# RP2040 register map
Vendor: Raspberry Pi; File version: 2025.06.15
CPU: CM0PLUS r0p1, little endian, 2 interrupt priority bits
Registers are 32-bit, read-write, no defined reset value unless marked. A register's access mark holds for its fields unless they carry their own. Offsets are from the block's base; [hi:lo] are bit positions; {n}, {i} and the like mark numbered series; 'fields as' and 'values as' point back to an identical list.

## USBCTRL_DPRAM — DPRAM layout for USB device.
Base 0x50100000
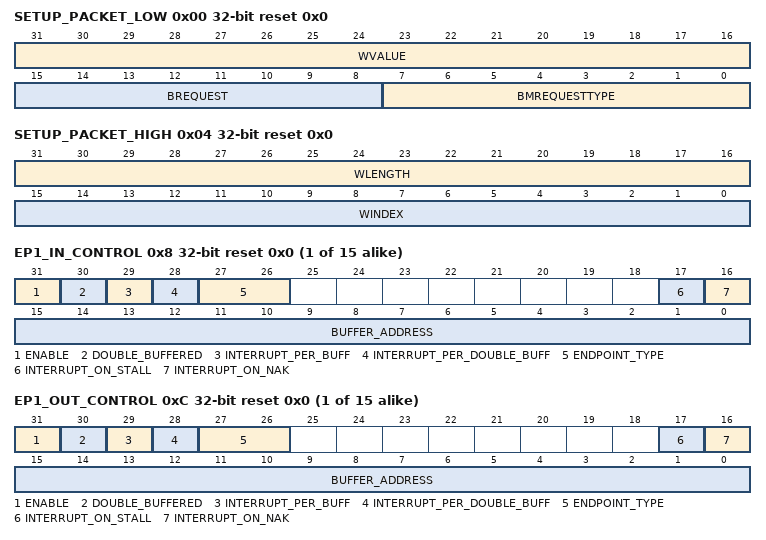
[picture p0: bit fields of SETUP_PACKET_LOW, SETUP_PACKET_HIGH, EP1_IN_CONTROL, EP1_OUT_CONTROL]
0x00 SETUP_PACKET_LOW reset 0x0 — Bytes 0-3 of the SETUP packet from the host.
  [31:16] WVALUE, [15:8] BREQUEST, [7:0] BMREQUESTTYPE
0x04 SETUP_PACKET_HIGH reset 0x0 — Bytes 4-7 of the setup packet from the host.
  [31:16] WLENGTH, [15:0] WINDEX
{0x0+8i} EP{i}_IN_CONTROL reset 0x0 (i=1..15)
  [31] ENABLE — Enable this endpoint. The device will not reply to any packets for this endpoint if this bit is not set.
  [30] DOUBLE_BUFFERED — This endpoint is double buffered.
  [29] INTERRUPT_PER_BUFF — Trigger an interrupt each time a buffer is done.
  [28] INTERRUPT_PER_DOUBLE_BUFF — Trigger an interrupt each time both buffers are done. Only valid in double buffered mode.
  [27:26] ENDPOINT_TYPE
    0=Control; 1=Isochronous; 2=Bulk; 3=Interrupt
  [17] INTERRUPT_ON_STALL — Trigger an interrupt if a STALL is sent. Intended for debug only.
  [16] INTERRUPT_ON_NAK — Trigger an interrupt if a NAK is sent. Intended for debug only.
  [15:0] BUFFER_ADDRESS — 64 byte aligned buffer address for this EP (bits 0-5 are ignored). Relative to the start of the DPRAM.
{0x4+8i} EP{i}_OUT_CONTROL reset 0x0 (i=1..15)
  fields as EP1_IN_CONTROL
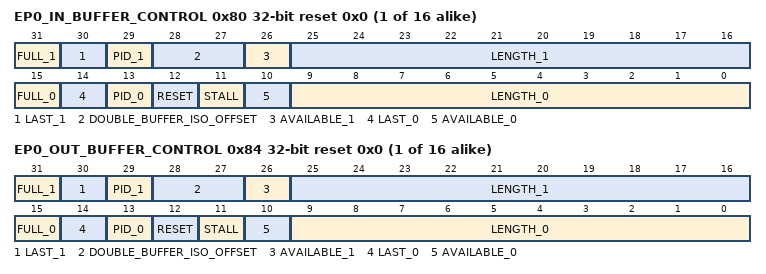
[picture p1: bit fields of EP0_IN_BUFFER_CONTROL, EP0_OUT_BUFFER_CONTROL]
{0x80+8i} EP{i}_IN_BUFFER_CONTROL reset 0x0 (i=0..15) — Buffer control for both buffers of an endpoint. Fields ending in a _1 are for buffer 1. Fields ending in a _0 are for buffer 0. Buffer 1 controls are only valid if the endpoint is in double buffered mode.
  [31] FULL_1 — Buffer 1 is full. For an IN transfer (TX to the host) the bit is set to indicate the data is valid. For an OUT transfer (RX from the host) this bit should be left as a 0. The host will set it when it has filled the buffer with data.
  [30] LAST_1 — Buffer 1 is the last buffer of the transfer.
  [29] PID_1 — The data pid of buffer 1.
  [28:27] DOUBLE_BUFFER_ISO_OFFSET — The number of bytes buffer 1 is offset from buffer 0 in Isochronous mode. Only valid in double buffered mode for an Isochronous endpoint. For a non Isochronous endpoint the offset is always 64 bytes.
    0=128; 1=256; 2=512; 3=1024
  [26] AVAILABLE_1 — Buffer 1 is available. This bit is set to indicate the buffer can be used by the controller. The controller clears the available bit when writing the status back.
  [25:16] LENGTH_1 — The length of the data in buffer 1.
  [15] FULL_0 — Buffer 0 is full. For an IN transfer (TX to the host) the bit is set to indicate the data is valid. For an OUT transfer (RX from the host) this bit should be left as a 0. The host will set it when it has filled the buffer with data.
  [14] LAST_0 — Buffer 0 is the last buffer of the transfer.
  [13] PID_0 — The data pid of buffer 0.
  [12] RESET — Reset the buffer selector to buffer 0.
  [11] STALL — Reply with a stall (valid for both buffers).
  [10] AVAILABLE_0 — Buffer 0 is available. This bit is set to indicate the buffer can be used by the controller. The controller clears the available bit when writing the status back.
  [9:0] LENGTH_0 — The length of the data in buffer 0.
{0x84+8i} EP{i}_OUT_BUFFER_CONTROL reset 0x0 (i=0..15) — Buffer control for both buffers of an endpoint. Fields ending in a _1 are for buffer 1. Fields ending in a _0 are for buffer 0. Buffer 1 controls are only valid if the endpoint is in double buffered mode.
  fields as EP0_IN_BUFFER_CONTROL

## VREG_AND_CHIP_RESET — control and status for on-chip voltage regulator and chip level reset subsystem
Base 0x40064000
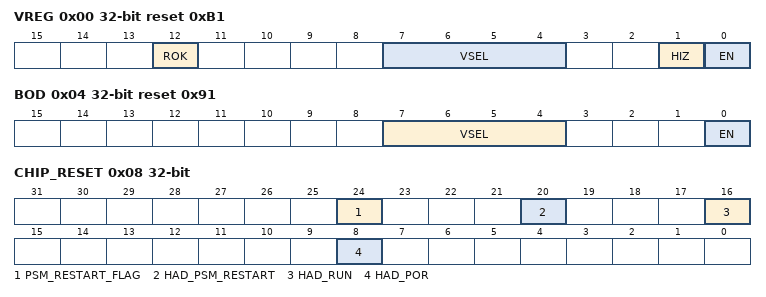
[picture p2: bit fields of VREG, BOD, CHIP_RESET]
0x00 VREG reset 0xB1 (reset mask 0x0) — Voltage regulator control and status
  [12] ROK ro — regulation status 0=not in regulation, 1=in regulation
  [7:4] VSEL — output voltage select 0000 to 0101 - 0.80V 0110 - 0.85V 0111 - 0.90V 1000 - 0.95V 1001 - 1.00V 1010 - 1.05V 1011 - 1.10V (default) 1100 - 1.15V 1101 - 1.20V 1110 - 1.25V 1111 - 1.30V
  [1] HIZ — high impedance mode select 0=not in high impedance mode, 1=in high impedance mode
  [0] EN — enable 0=not enabled, 1=enabled
0x04 BOD reset 0x91 (reset mask 0x0) — brown-out detection control
  [7:4] VSEL — threshold select 0000 - 0.473V 0001 - 0.516V 0010 - 0.559V 0011 - 0.602V 0100 - 0.645V 0101 - 0.688V 0110 - 0.731V 0111 - 0.774V 1000 - 0.817V 1001 - 0.860V (default) 1010 - 0.903V 1011 - 0.946V 1100 - 0.989V 1101 - 1.032V 1110 - 1.075V 1111 - 1.118V
  [0] EN — enable 0=not enabled, 1=enabled
0x08 CHIP_RESET — Chip reset control and status
  [24] PSM_RESTART_FLAG write-1-clears — This is set by psm_restart from the debugger. Its purpose is to branch bootcode to a safe mode when the debugger has issued a psm_restart in order to recover from a boot lock-up. In the safe mode the debugger can repair the boot code, clear this flag then reboot the processor.
  [20] HAD_PSM_RESTART ro — Last reset was from the debug port
  [16] HAD_RUN ro — Last reset was from the RUN pin
  [8] HAD_POR ro — Last reset was from the power-on reset or brown-out detection blocks
